CM_ "AUTOGENERATED FILE, DO NOT EDIT";

CM_ "hyundai_mrrevo14f_radar.dbc starts here";

VERSION ""

NS_ :

BS_:

BU_: XXX

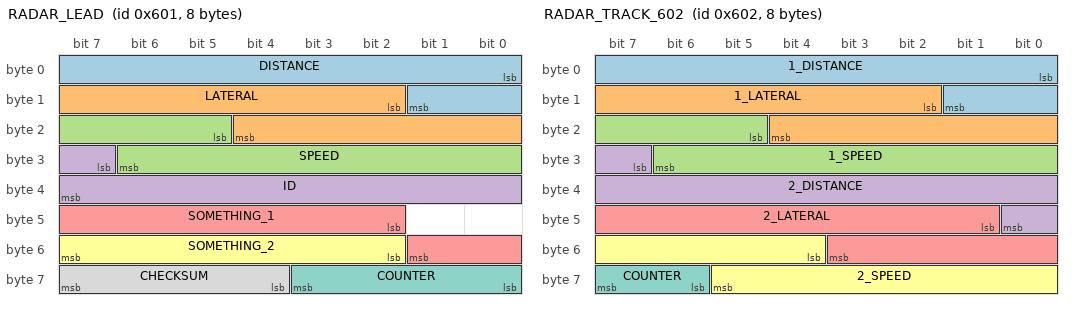
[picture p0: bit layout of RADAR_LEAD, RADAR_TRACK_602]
BO_ 1537 RADAR_LEAD: 8 RADAR
 SG_ DISTANCE : 0|10@1+ (0.25,0) [0|255.75] "" XXX
 SG_ LATERAL : 10|11@1+ (0.03,-30.705) [-30.705|30.705] "" XXX
 SG_ SPEED : 21|10@1+ (0.25,-128) [-128|127.75] "" XXX
 SG_ ID : 31|9@1+ (1,0) [0|511] "" XXX
 SG_ SOMETHING_1 : 42|8@1+ (1,-128) [-128|127] "" XXX
 SG_ SOMETHING_2 : 50|6@1+ (1,-32) [-32|31] "" XXX
 SG_ COUNTER : 56|4@1+ (1,0) [0|15] "" XXX
 SG_ CHECKSUM : 63|4@0+ (1,0) [0|15] "" XXX

BO_ 1538 RADAR_TRACK_602: 8 RADAR
 SG_ 1_DISTANCE : 0|10@1+ (0.25,0) [0|255.75] "" XXX
 SG_ 1_LATERAL : 10|11@1+ (0.03,-30.705) [-30.705|30.705] "" XXX
 SG_ 1_SPEED : 21|10@1+ (0.25,-128) [-128|127.75] "" XXX
 SG_ 2_DISTANCE : 31|10@1+ (0.25,0) [0|255.75] "" XXX
 SG_ 2_LATERAL : 41|11@1+ (0.03,-30.705) [-30.705|30.705] "" XXX
 SG_ 2_SPEED : 52|10@1+ (0.25,-128) [-128|127.75] "" XXX
 SG_ COUNTER : 62|2@1+ (1,0) [0|3] "" XXX

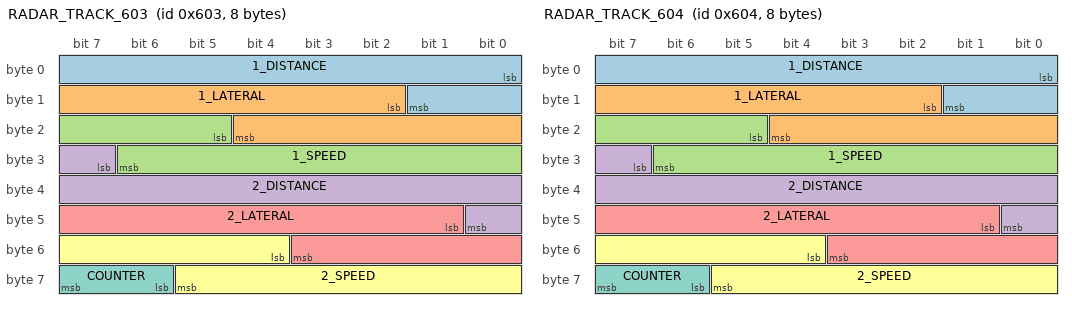
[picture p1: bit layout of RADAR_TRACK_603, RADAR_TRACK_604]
BO_ 1539 RADAR_TRACK_603: 8 RADAR
 SG_ 1_DISTANCE : 0|10@1+ (0.25,0) [0|255.75] "" XXX
 SG_ 1_LATERAL : 10|11@1+ (0.03,-30.705) [-30.705|30.705] "" XXX
 SG_ 1_SPEED : 21|10@1+ (0.25,-128) [-128|127.75] "" XXX
 SG_ 2_DISTANCE : 31|10@1+ (0.25,0) [0|255.75] "" XXX
 SG_ 2_LATERAL : 41|11@1+ (0.03,-30.705) [-30.705|30.705] "" XXX
 SG_ 2_SPEED : 52|10@1+ (0.25,-128) [-128|127.75] "" XXX
 SG_ COUNTER : 62|2@1+ (1,0) [0|3] "" XXX

BO_ 1540 RADAR_TRACK_604: 8 RADAR
 SG_ 1_DISTANCE : 0|10@1+ (0.25,0) [0|255.75] "" XXX
 SG_ 1_LATERAL : 10|11@1+ (0.03,-30.705) [-30.705|30.705] "" XXX
 SG_ 1_SPEED : 21|10@1+ (0.25,-128) [-128|127.75] "" XXX
 SG_ 2_DISTANCE : 31|10@1+ (0.25,0) [0|255.75] "" XXX
 SG_ 2_LATERAL : 41|11@1+ (0.03,-30.705) [-30.705|30.705] "" XXX
 SG_ 2_SPEED : 52|10@1+ (0.25,-128) [-128|127.75] "" XXX
 SG_ COUNTER : 62|2@1+ (1,0) [0|3] "" XXX

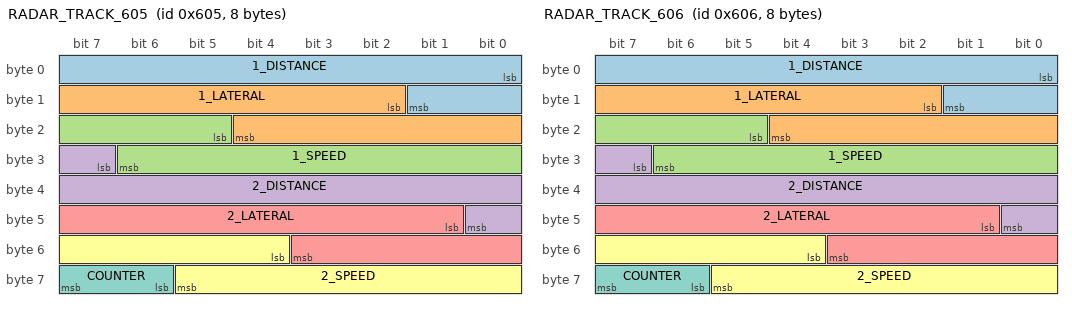
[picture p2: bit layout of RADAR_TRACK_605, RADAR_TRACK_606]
BO_ 1541 RADAR_TRACK_605: 8 RADAR
 SG_ 1_DISTANCE : 0|10@1+ (0.25,0) [0|255.75] "" XXX
 SG_ 1_LATERAL : 10|11@1+ (0.03,-30.705) [-30.705|30.705] "" XXX
 SG_ 1_SPEED : 21|10@1+ (0.25,-128) [-128|127.75] "" XXX
 SG_ 2_DISTANCE : 31|10@1+ (0.25,0) [0|255.75] "" XXX
 SG_ 2_LATERAL : 41|11@1+ (0.03,-30.705) [-30.705|30.705] "" XXX
 SG_ 2_SPEED : 52|10@1+ (0.25,-128) [-128|127.75] "" XXX
 SG_ COUNTER : 62|2@1+ (1,0) [0|3] "" XXX

BO_ 1542 RADAR_TRACK_606: 8 RADAR
 SG_ 1_DISTANCE : 0|10@1+ (0.25,0) [0|255.75] "" XXX
 SG_ 1_LATERAL : 10|11@1+ (0.03,-30.705) [-30.705|30.705] "" XXX
 SG_ 1_SPEED : 21|10@1+ (0.25,-128) [-128|127.75] "" XXX
 SG_ 2_DISTANCE : 31|10@1+ (0.25,0) [0|255.75] "" XXX
 SG_ 2_LATERAL : 41|11@1+ (0.03,-30.705) [-30.705|30.705] "" XXX
 SG_ 2_SPEED : 52|10@1+ (0.25,-128) [-128|127.75] "" XXX
 SG_ COUNTER : 62|2@1+ (1,0) [0|3] "" XXX

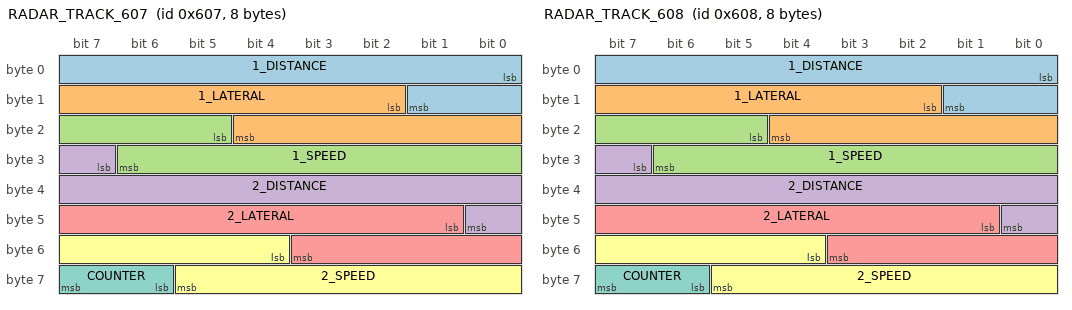
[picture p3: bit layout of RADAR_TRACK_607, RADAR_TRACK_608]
BO_ 1543 RADAR_TRACK_607: 8 RADAR
 SG_ 1_DISTANCE : 0|10@1+ (0.25,0) [0|255.75] "" XXX
 SG_ 1_LATERAL : 10|11@1+ (0.03,-30.705) [-30.705|30.705] "" XXX
 SG_ 1_SPEED : 21|10@1+ (0.25,-128) [-128|127.75] "" XXX
 SG_ 2_DISTANCE : 31|10@1+ (0.25,0) [0|255.75] "" XXX
 SG_ 2_LATERAL : 41|11@1+ (0.03,-30.705) [-30.705|30.705] "" XXX
 SG_ 2_SPEED : 52|10@1+ (0.25,-128) [-128|127.75] "" XXX
 SG_ COUNTER : 62|2@1+ (1,0) [0|3] "" XXX

BO_ 1544 RADAR_TRACK_608: 8 RADAR
 SG_ 1_DISTANCE : 0|10@1+ (0.25,0) [0|255.75] "" XXX
 SG_ 1_LATERAL : 10|11@1+ (0.03,-30.705) [-30.705|30.705] "" XXX
 SG_ 1_SPEED : 21|10@1+ (0.25,-128) [-128|127.75] "" XXX
 SG_ 2_DISTANCE : 31|10@1+ (0.25,0) [0|255.75] "" XXX
 SG_ 2_LATERAL : 41|11@1+ (0.03,-30.705) [-30.705|30.705] "" XXX
 SG_ 2_SPEED : 52|10@1+ (0.25,-128) [-128|127.75] "" XXX
 SG_ COUNTER : 62|2@1+ (1,0) [0|3] "" XXX

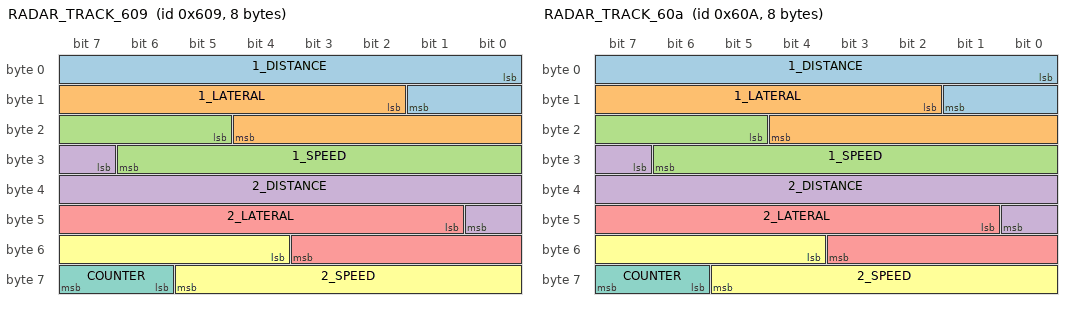
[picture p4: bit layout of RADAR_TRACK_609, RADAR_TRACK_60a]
BO_ 1545 RADAR_TRACK_609: 8 RADAR
 SG_ 1_DISTANCE : 0|10@1+ (0.25,0) [0|255.75] "" XXX
 SG_ 1_LATERAL : 10|11@1+ (0.03,-30.705) [-30.705|30.705] "" XXX
 SG_ 1_SPEED : 21|10@1+ (0.25,-128) [-128|127.75] "" XXX
 SG_ 2_DISTANCE : 31|10@1+ (0.25,0) [0|255.75] "" XXX
 SG_ 2_LATERAL : 41|11@1+ (0.03,-30.705) [-30.705|30.705] "" XXX
 SG_ 2_SPEED : 52|10@1+ (0.25,-128) [-128|127.75] "" XXX
 SG_ COUNTER : 62|2@1+ (1,0) [0|3] "" XXX

BO_ 1546 RADAR_TRACK_60a: 8 RADAR
 SG_ 1_DISTANCE : 0|10@1+ (0.25,0) [0|255.75] "" XXX
 SG_ 1_LATERAL : 10|11@1+ (0.03,-30.705) [-30.705|30.705] "" XXX
 SG_ 1_SPEED : 21|10@1+ (0.25,-128) [-128|127.75] "" XXX
 SG_ 2_DISTANCE : 31|10@1+ (0.25,0) [0|255.75] "" XXX
 SG_ 2_LATERAL : 41|11@1+ (0.03,-30.705) [-30.705|30.705] "" XXX
 SG_ 2_SPEED : 52|10@1+ (0.25,-128) [-128|127.75] "" XXX
 SG_ COUNTER : 62|2@1+ (1,0) [0|3] "" XXX

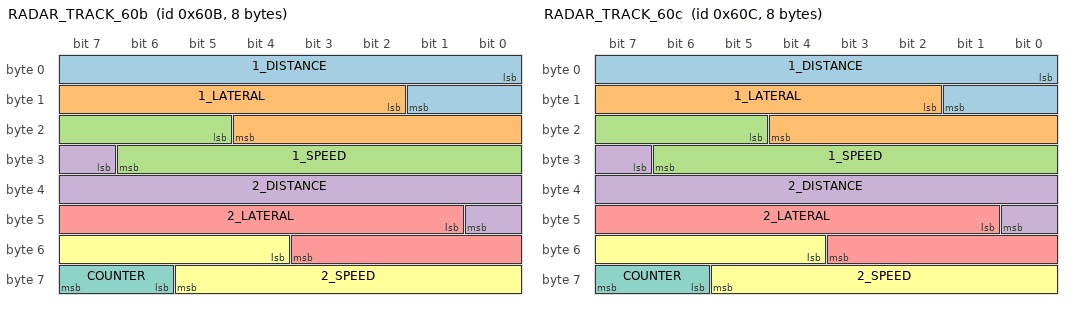
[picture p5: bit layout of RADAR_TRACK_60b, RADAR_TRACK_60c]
BO_ 1547 RADAR_TRACK_60b: 8 RADAR
 SG_ 1_DISTANCE : 0|10@1+ (0.25,0) [0|255.75] "" XXX
 SG_ 1_LATERAL : 10|11@1+ (0.03,-30.705) [-30.705|30.705] "" XXX
 SG_ 1_SPEED : 21|10@1+ (0.25,-128) [-128|127.75] "" XXX
 SG_ 2_DISTANCE : 31|10@1+ (0.25,0) [0|255.75] "" XXX
 SG_ 2_LATERAL : 41|11@1+ (0.03,-30.705) [-30.705|30.705] "" XXX
 SG_ 2_SPEED : 52|10@1+ (0.25,-128) [-128|127.75] "" XXX
 SG_ COUNTER : 62|2@1+ (1,0) [0|3] "" XXX

BO_ 1548 RADAR_TRACK_60c: 8 RADAR
 SG_ 1_DISTANCE : 0|10@1+ (0.25,0) [0|255.75] "" XXX
 SG_ 1_LATERAL : 10|11@1+ (0.03,-30.705) [-30.705|30.705] "" XXX
 SG_ 1_SPEED : 21|10@1+ (0.25,-128) [-128|127.75] "" XXX
 SG_ 2_DISTANCE : 31|10@1+ (0.25,0) [0|255.75] "" XXX
 SG_ 2_LATERAL : 41|11@1+ (0.03,-30.705) [-30.705|30.705] "" XXX
 SG_ 2_SPEED : 52|10@1+ (0.25,-128) [-128|127.75] "" XXX
 SG_ COUNTER : 62|2@1+ (1,0) [0|3] "" XXX

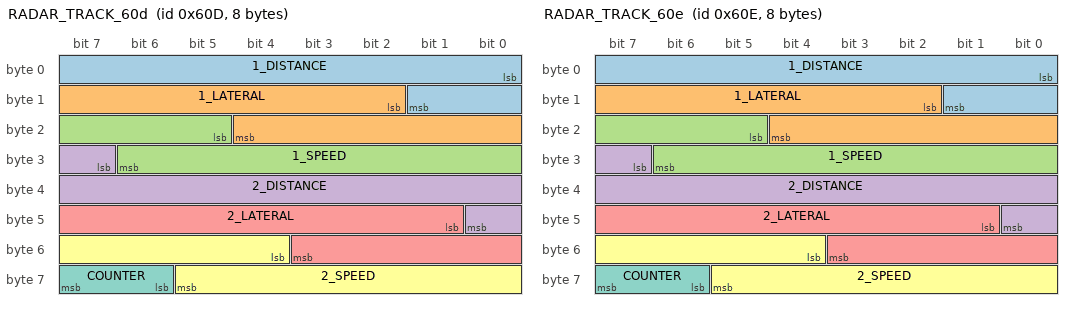
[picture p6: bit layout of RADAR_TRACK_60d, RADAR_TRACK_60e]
BO_ 1549 RADAR_TRACK_60d: 8 RADAR
 SG_ 1_DISTANCE : 0|10@1+ (0.25,0) [0|255.75] "" XXX
 SG_ 1_LATERAL : 10|11@1+ (0.03,-30.705) [-30.705|30.705] "" XXX
 SG_ 1_SPEED : 21|10@1+ (0.25,-128) [-128|127.75] "" XXX
 SG_ 2_DISTANCE : 31|10@1+ (0.25,0) [0|255.75] "" XXX
 SG_ 2_LATERAL : 41|11@1+ (0.03,-30.705) [-30.705|30.705] "" XXX
 SG_ 2_SPEED : 52|10@1+ (0.25,-128) [-128|127.75] "" XXX
 SG_ COUNTER : 62|2@1+ (1,0) [0|3] "" XXX

BO_ 1550 RADAR_TRACK_60e: 8 RADAR
 SG_ 1_DISTANCE : 0|10@1+ (0.25,0) [0|255.75] "" XXX
 SG_ 1_LATERAL : 10|11@1+ (0.03,-30.705) [-30.705|30.705] "" XXX
 SG_ 1_SPEED : 21|10@1+ (0.25,-128) [-128|127.75] "" XXX
 SG_ 2_DISTANCE : 31|10@1+ (0.25,0) [0|255.75] "" XXX
 SG_ 2_LATERAL : 41|11@1+ (0.03,-30.705) [-30.705|30.705] "" XXX
 SG_ 2_SPEED : 52|10@1+ (0.25,-128) [-128|127.75] "" XXX
 SG_ COUNTER : 62|2@1+ (1,0) [0|3] "" XXX

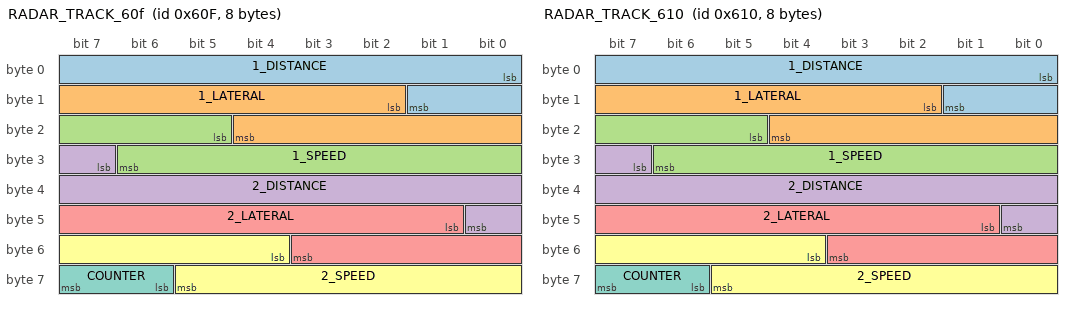
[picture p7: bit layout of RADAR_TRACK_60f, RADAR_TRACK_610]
BO_ 1551 RADAR_TRACK_60f: 8 RADAR
 SG_ 1_DISTANCE : 0|10@1+ (0.25,0) [0|255.75] "" XXX
 SG_ 1_LATERAL : 10|11@1+ (0.03,-30.705) [-30.705|30.705] "" XXX
 SG_ 1_SPEED : 21|10@1+ (0.25,-128) [-128|127.75] "" XXX
 SG_ 2_DISTANCE : 31|10@1+ (0.25,0) [0|255.75] "" XXX
 SG_ 2_LATERAL : 41|11@1+ (0.03,-30.705) [-30.705|30.705] "" XXX
 SG_ 2_SPEED : 52|10@1+ (0.25,-128) [-128|127.75] "" XXX
 SG_ COUNTER : 62|2@1+ (1,0) [0|3] "" XXX

BO_ 1552 RADAR_TRACK_610: 8 RADAR
 SG_ 1_DISTANCE : 0|10@1+ (0.25,0) [0|255.75] "" XXX
 SG_ 1_LATERAL : 10|11@1+ (0.03,-30.705) [-30.705|30.705] "" XXX
 SG_ 1_SPEED : 21|10@1+ (0.25,-128) [-128|127.75] "" XXX
 SG_ 2_DISTANCE : 31|10@1+ (0.25,0) [0|255.75] "" XXX
 SG_ 2_LATERAL : 41|11@1+ (0.03,-30.705) [-30.705|30.705] "" XXX
 SG_ 2_SPEED : 52|10@1+ (0.25,-128) [-128|127.75] "" XXX
 SG_ COUNTER : 62|2@1+ (1,0) [0|3] "" XXX

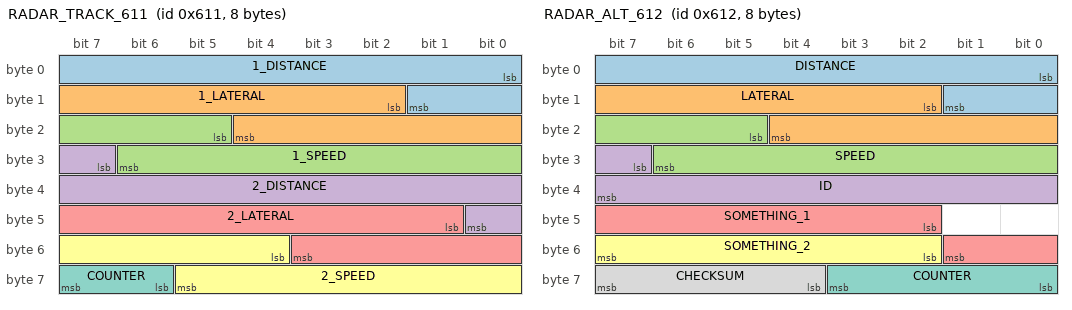
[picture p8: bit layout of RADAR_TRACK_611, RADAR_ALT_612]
BO_ 1553 RADAR_TRACK_611: 8 RADAR
 SG_ 1_DISTANCE : 0|10@1+ (0.25,0) [0|255.75] "" XXX
 SG_ 1_LATERAL : 10|11@1+ (0.03,-30.705) [-30.705|30.705] "" XXX
 SG_ 1_SPEED : 21|10@1+ (0.25,-128) [-128|127.75] "" XXX
 SG_ 2_DISTANCE : 31|10@1+ (0.25,0) [0|255.75] "" XXX
 SG_ 2_LATERAL : 41|11@1+ (0.03,-30.705) [-30.705|30.705] "" XXX
 SG_ 2_SPEED : 52|10@1+ (0.25,-128) [-128|127.75] "" XXX
 SG_ COUNTER : 62|2@1+ (1,0) [0|3] "" XXX

BO_ 1554 RADAR_ALT_612: 8 RADAR
 SG_ DISTANCE : 0|10@1+ (0.25,0) [0|255.75] "" XXX
 SG_ LATERAL : 10|11@1+ (0.03,-30.705) [-30.705|30.705] "" XXX
 SG_ SPEED : 21|10@1+ (0.25,-128) [-128|127.75] "" XXX
 SG_ ID : 31|9@1+ (1,0) [0|511] "" XXX
 SG_ SOMETHING_1 : 42|8@1+ (1,-128) [-128|127] "" XXX
 SG_ SOMETHING_2 : 50|6@1+ (1,-32) [-32|31] "" XXX
 SG_ COUNTER : 56|4@1+ (1,0) [0|15] "" XXX
 SG_ CHECKSUM : 63|4@0+ (1,0) [0|15] "" XXX

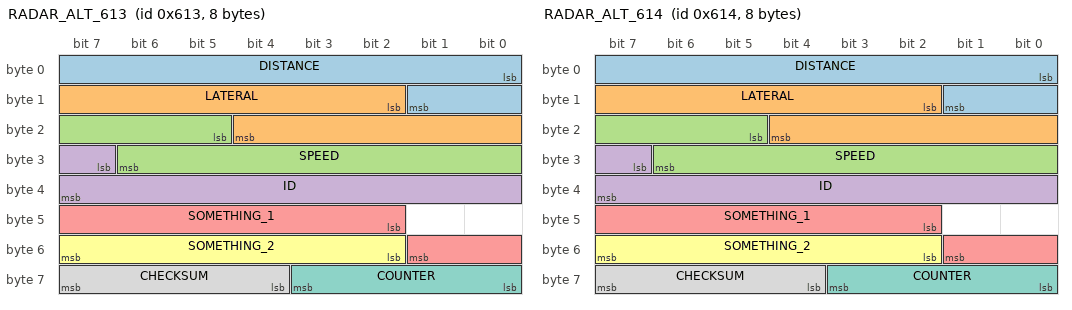
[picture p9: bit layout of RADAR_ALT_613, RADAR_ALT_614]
BO_ 1555 RADAR_ALT_613: 8 RADAR
 SG_ DISTANCE : 0|10@1+ (0.25,0) [0|255.75] "" XXX
 SG_ LATERAL : 10|11@1+ (0.03,-30.705) [-30.705|30.705] "" XXX
 SG_ SPEED : 21|10@1+ (0.25,-128) [-128|127.75] "" XXX
 SG_ ID : 31|9@1+ (1,0) [0|511] "" XXX
 SG_ SOMETHING_1 : 42|8@1+ (1,-128) [-128|127] "" XXX
 SG_ SOMETHING_2 : 50|6@1+ (1,-32) [-32|31] "" XXX
 SG_ COUNTER : 56|4@1+ (1,0) [0|15] "" XXX
 SG_ CHECKSUM : 63|4@0+ (1,0) [0|15] "" XXX

BO_ 1556 RADAR_ALT_614: 8 RADAR
 SG_ DISTANCE : 0|10@1+ (0.25,0) [0|255.75] "" XXX
 SG_ LATERAL : 10|11@1+ (0.03,-30.705) [-30.705|30.705] "" XXX
 SG_ SPEED : 21|10@1+ (0.25,-128) [-128|127.75] "" XXX
 SG_ ID : 31|9@1+ (1,0) [0|511] "" XXX
 SG_ SOMETHING_1 : 42|8@1+ (1,-128) [-128|127] "" XXX
 SG_ SOMETHING_2 : 50|6@1+ (1,-32) [-32|31] "" XXX
 SG_ COUNTER : 56|4@1+ (1,0) [0|15] "" XXX
 SG_ CHECKSUM : 63|4@0+ (1,0) [0|15] "" XXX

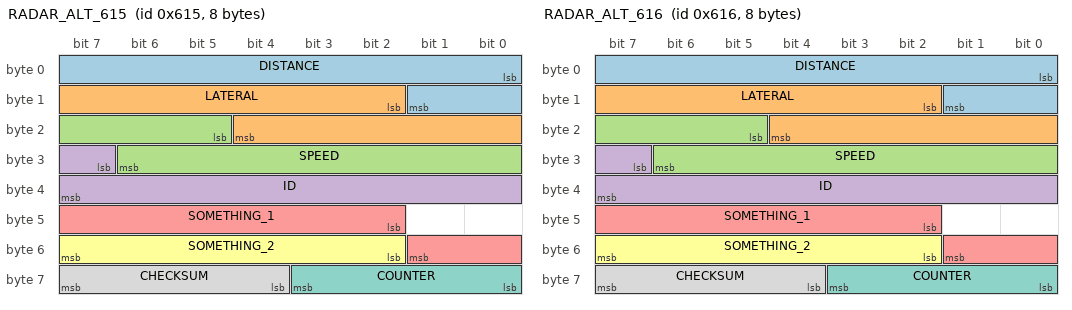
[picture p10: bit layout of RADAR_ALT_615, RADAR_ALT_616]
BO_ 1557 RADAR_ALT_615: 8 RADAR
 SG_ DISTANCE : 0|10@1+ (0.25,0) [0|255.75] "" XXX
 SG_ LATERAL : 10|11@1+ (0.03,-30.705) [-30.705|30.705] "" XXX
 SG_ SPEED : 21|10@1+ (0.25,-128) [-128|127.75] "" XXX
 SG_ ID : 31|9@1+ (1,0) [0|511] "" XXX
 SG_ SOMETHING_1 : 42|8@1+ (1,-128) [-128|127] "" XXX
 SG_ SOMETHING_2 : 50|6@1+ (1,-32) [-32|31] "" XXX
 SG_ COUNTER : 56|4@1+ (1,0) [0|15] "" XXX
 SG_ CHECKSUM : 63|4@0+ (1,0) [0|15] "" XXX

BO_ 1558 RADAR_ALT_616: 8 RADAR
 SG_ DISTANCE : 0|10@1+ (0.25,0) [0|255.75] "" XXX
 SG_ LATERAL : 10|11@1+ (0.03,-30.705) [-30.705|30.705] "" XXX
 SG_ SPEED : 21|10@1+ (0.25,-128) [-128|127.75] "" XXX
 SG_ ID : 31|9@1+ (1,0) [0|511] "" XXX
 SG_ SOMETHING_1 : 42|8@1+ (1,-128) [-128|127] "" XXX
 SG_ SOMETHING_2 : 50|6@1+ (1,-32) [-32|31] "" XXX
 SG_ COUNTER : 56|4@1+ (1,0) [0|15] "" XXX
 SG_ CHECKSUM : 63|4@0+ (1,0) [0|15] "" XXX

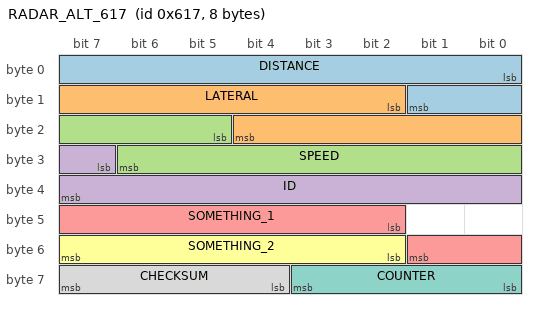
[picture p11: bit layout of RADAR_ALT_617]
BO_ 1559 RADAR_ALT_617: 8 RADAR
 SG_ DISTANCE : 0|10@1+ (0.25,0) [0|255.75] "" XXX
 SG_ LATERAL : 10|11@1+ (0.03,-30.705) [-30.705|30.705] "" XXX
 SG_ SPEED : 21|10@1+ (0.25,-128) [-128|127.75] "" XXX
 SG_ ID : 31|9@1+ (1,0) [0|511] "" XXX
 SG_ SOMETHING_1 : 42|8@1+ (1,-128) [-128|127] "" XXX
 SG_ SOMETHING_2 : 50|6@1+ (1,-32) [-32|31] "" XXX
 SG_ COUNTER : 56|4@1+ (1,0) [0|15] "" XXX
 SG_ CHECKSUM : 63|4@0+ (1,0) [0|15] "" XXX
